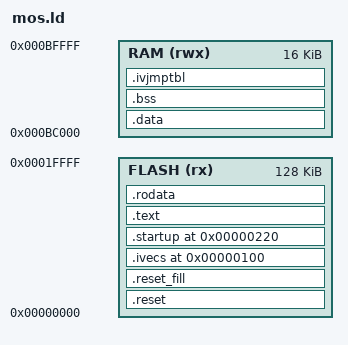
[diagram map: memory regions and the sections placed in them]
/*
 * Agon Platform MOS firmware layout for the eZ80F92.
 *
 * This reproduces the memory and startup contract emitted by the current
 * ZDS II Release link.  It deliberately does not provide a C runtime: reset,
 * vector, startup, and runtime objects must define the required contents.
 */

OUTPUT_FORMAT("elf32-z80")
ENTRY(_reset)

MEMORY
{
    FLASH (rx)  : ORIGIN = 0x000000, LENGTH = 0x020000
    RAM   (rwx) : ORIGIN = 0x0BC000, LENGTH = 0x004000
}

/* Values generated by the ZDS target and Release linker configuration. */
__CS0_LBR_INIT_PARAM       = 0x04;
__CS0_UBR_INIT_PARAM       = 0x0B;
__CS0_CTL_INIT_PARAM       = 0x08;
__CS0_BMC_INIT_PARAM       = 0x01;
__CS1_LBR_INIT_PARAM       = 0xC0;
__CS1_UBR_INIT_PARAM       = 0xC7;
__CS1_CTL_INIT_PARAM       = 0x08;
__CS1_BMC_INIT_PARAM       = 0x00;
__CS2_LBR_INIT_PARAM       = 0x80;
__CS2_UBR_INIT_PARAM       = 0xBF;
__CS2_CTL_INIT_PARAM       = 0x08;
__CS2_BMC_INIT_PARAM       = 0x00;
__CS3_LBR_INIT_PARAM       = 0x03;
__CS3_UBR_INIT_PARAM       = 0x03;
__CS3_CTL_INIT_PARAM       = 0x18;
__CS3_BMC_INIT_PARAM       = 0x82;
__RAM_CTL_INIT_PARAM       = 0x80;
__RAM_ADDR_U_INIT_PARAM    = 0xB7;
__FLASH_CTL_INIT_PARAM     = 0x28;
__FLASH_ADDR_U_INIT_PARAM  = 0x00;
_SYS_CLK_FREQ              = 18432000;

/* MOS executes from flash.  cstartup retains the generic Zilog symbols. */
__copy_code_to_ram = 0;
__crtl             = 1;
__low_rom          = ORIGIN(FLASH);

SECTIONS
{
    /* Reset and RST handlers occupy the first flash page. */
    .reset ORIGIN(FLASH) :
    {
        __reset_start = .;
        KEEP(*(.reset .RESET))
        __reset_end = .;
    } > FLASH

    /*
     * Preserve the erased-flash bytes up to the fixed vectors.  A build may
     * place Fab's optional 0x4F-byte hostfs descriptor at address 0x6B.
     */
    .reset_fill :
    {
        __mos_descriptor_start = .;
        KEEP(*(.mos_descriptor))
        __mos_descriptor_end = .;
        FILL(0xFF)
        BYTE(0xFF)
        . = 0x000095;
    } > FLASH

    /*
     * The 48-entry IM 2 vector table begins at 0x100 and is followed by the
     * 48 four-byte first-level jumps.  vectors16.asm therefore contributes
     * exactly 0x120 bytes here.
     */
    .ivecs 0x000100 :
    {
        __ivecs_start = .;
        KEEP(*(.ivecs .IVECTS .vectors))
        __ivecs_end = .;
    } > FLASH

    /* The ZDS ordering contract begins all startup code at 0x220. */
    .startup 0x000220 :
    {
        __startup_start = .;
        KEEP(*(.startup .STARTUP))
        __startup_end = .;
    } > FLASH

    /* Executable code follows startup, preserving input-file order. */
    .text :
    {
        __low_code = .;
        *(.text .text.*)
        *(CODE CODE.* .CODE .CODE.*)
        __code_end = .;
    } > FLASH
    __low_romcode = LOADADDR(.text);
    __len_code = SIZEOF(.text);

    /* Read-only compiler tables and strings remain in flash. */
    .rodata :
    {
        *(.rodata .rodata.* .srodata .srodata.*)
        *(TEXT TEXT.* .TEXT .TEXT.*)
        *(STRSECT STRSECT.* .STRSECT .STRSECT.*)
    } > FLASH
    __rom_ro_end = .;

    /*
     * Initialized data executes at the start of internal RAM, but its bytes
     * are stored immediately after the read-only flash payload.  cstartup
     * copies [__low_romdata, __len_data] to __low_data.
     */
    .data ORIGIN(RAM) : AT(__rom_ro_end)
    {
        __low_data = .;
        *(.data .data.* .sdata .sdata.*)
        *(DATA DATA.* .DATA .DATA.*)
        __data_end = .;
    } > RAM
    __low_romdata = LOADADDR(.data);
    __len_data = SIZEOF(.data);

    /* cstartup clears this complete range before initialized data is used. */
    .bss (NOLOAD) :
    {
        __low_bss = .;
        *(.bss .bss.* .sbss .sbss.*)
        *(BSS BSS.* .BSS .BSS.*)
        *(COMMON)
        __bss_end = .;
    } > RAM
    __len_bss = SIZEOF(.bss);

    /* The writable second-level table contains 48 four-byte JP entries. */
    .ivjmptbl (NOLOAD) :
    {
        __ivjmptbl_start = .;
        KEEP(*(.ivjmptbl .ivjmptbl.* IVJMPTBL IVJMPTBL.*))
        __ivjmptbl_end = .;
    } > RAM

    /* Preserve the ZDS heap/stack symbols used by MOS C source. */
    __ram_static_end = ADDR(.ivjmptbl) + SIZEOF(.ivjmptbl);
    __heapbot = __ram_static_end;
    __heaptop = ORIGIN(RAM) + LENGTH(RAM) - 1;
    __stack = ORIGIN(RAM) + LENGTH(RAM);
    __stack_reserve = 0x0800;
    __stack_bottom = __stack - __stack_reserve;
    __heap_limit = __stack_bottom;

    __rom_image_end = LOADADDR(.data) + SIZEOF(.data);

    /DISCARD/ :
    {
        *(.comment)
        *(.note .note.*)
        *(.eh_frame .eh_frame.*)
        *(.gnu.attributes)
    }
}

ASSERT(DEFINED(_reset), "MOS link requires a global _reset entry point")
ASSERT(ADDR(.reset) == ORIGIN(FLASH), "reset must begin at flash address 0")
ASSERT(SIZEOF(.reset) > 0, "reset section must not be empty")
ASSERT(__reset_end <= 0x00006B,
       "reset section overlaps the optional descriptor slot at 0x6B")
ASSERT((__mos_descriptor_end - __mos_descriptor_start) == 0 ||
       (__mos_descriptor_end - __mos_descriptor_start) == 0x4F,
       "Fab MOS descriptor table must be exactly 0x4F bytes when present")

ASSERT(ADDR(.ivecs) == 0x000100, "interrupt vectors must begin at 0x100")
ASSERT((ADDR(.ivecs) & 0xFF) == 0, "interrupt vectors must be 256-byte aligned")
ASSERT(SIZEOF(.ivecs) == 0x000120,
       "interrupt vectors and first jump table must occupy exactly 0x120 bytes")
ASSERT(ADDR(.startup) == 0x000220, "startup must begin at 0x220")
ASSERT(SIZEOF(.startup) > 0, "startup section must not be empty")

ASSERT(ADDR(.data) == ORIGIN(RAM), "initialized data must begin at 0x0BC000")
ASSERT(__low_bss >= __data_end, "BSS overlaps initialized data")
ASSERT(__ivjmptbl_start >= __bss_end, "RAM interrupt jump table overlaps BSS")
ASSERT(SIZEOF(.ivjmptbl) == 0x0000C0,
       "second interrupt jump table must contain 48 four-byte entries")

ASSERT(__rom_image_end <= ORIGIN(FLASH) + LENGTH(FLASH),
       "MOS firmware image exceeds the 128 KiB flash window")
ASSERT(__ram_static_end <= __stack,
       "MOS static sections exceed the 16 KiB internal RAM window")
ASSERT(__heapbot <= __stack_bottom,
       "MOS static sections consume the reserved 2 KiB stack")
